# S6E1C3xD register map
Vendor: Cypress; File version: 2.1
CPU: CM0PLUS r0p1, little endian, no MPU, no FPU, 2 interrupt priority bits
Registers are 32-bit, read-write, reset 0x0 unless marked. A register's access mark holds for its fields unless they carry their own. Offsets are from the block's base; [hi:lo] are bit positions; {n}, {i} and the like mark numbered series.

## LVD — Low-voltage Detection
Base 0x40035000
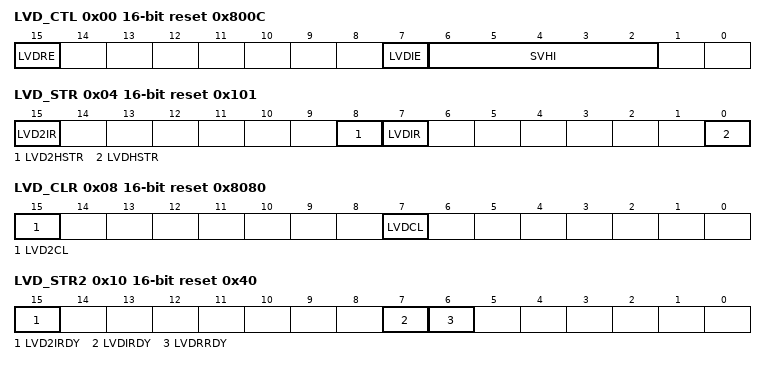
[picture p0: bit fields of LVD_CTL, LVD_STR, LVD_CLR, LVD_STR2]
0x00 LVD_CTL 16-bit reset 0x800C — Low-voltage Detection Voltage Control Register [BHW]
  [15] LVDRE — Low-voltage detection reset operation enable bit
  [7] LVDIE — Low-voltage detection interrupt enable bit
  [6:2] SVHI — Low-voltage detection interrupt voltage setting bits
0x04 LVD_STR 16-bit ro reset 0x101 — Low-voltage Detection Interrupt Factor Register [BHW]
  [15] LVD2IR — Low-voltage detection 2 interrupt factor bit
  [8] LVD2HSTR — Voltage of VCC is higher than the setting of SVH2RLI
  [7] LVDIR — Low-voltage detection interrupt factor bit
  [0] LVDHSTR — Voltage of VCC is higher than the setting of SVHRLI
0x08 LVD_CLR 16-bit reset 0x8080 — Low-voltage Detection Interrupt Factor Clear Register [BHW]
  [15] LVD2CL — Low-voltage detection 2 interrupt factor clear bit
  [7] LVDCL — Low-voltage detection interrupt factor clear bit
0x0C LVD_RLR reset 0x1 — Low-voltage Detection Voltage Protection Register [W]
  [31:0] LVDLCK — Low-voltage Detection Voltage Control Register protection bits
0x10 LVD_STR2 16-bit ro reset 0x40 — Low-voltage Detection Circuit Status Register [BHW]
  [15] LVD2IRDY — Low-voltage detection 2 interrupt status flag
  [7] LVDIRDY — Low-voltage detection interrupt status flag
  [6] LVDRRDY — Low-voltage detection reset status flag

## DS — Low Power Consumption Mode Registers
Base 0x40035100
0x00 REG_CTL 8-bit reset 0x4 — Sub Oscillation Circuit Power Supply Control Register [BHW]
  [2:1] ISUBSEL — Sub oscillation circuit current setting bits
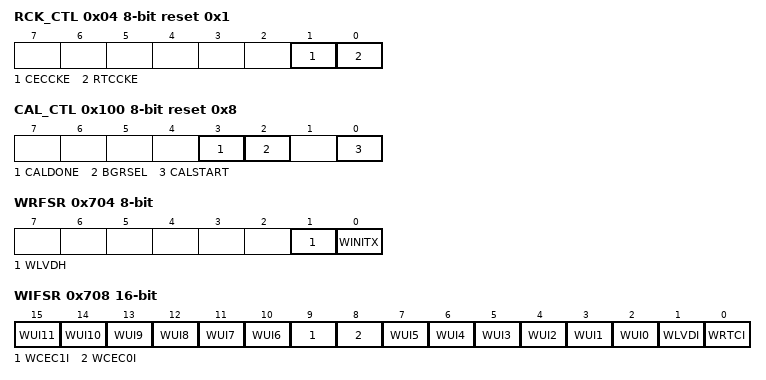
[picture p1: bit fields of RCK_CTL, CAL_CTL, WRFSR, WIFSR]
0x04 RCK_CTL 8-bit reset 0x1 — Sub Clock Control Register [BHW]
  [1] CECCKE — CEC clock control bit
  [0] RTCCKE — RTC clock control bit
0x10 MOSC_CTL 8-bit reset 0x4 — Main Oscillation Crystal Type Selection Control Register [BHW]
  [2:1] IMAINSEL — Main oscillation circuit current setting bits
0x100 CAL_CTL 8-bit reset 0x8 — Vref Calibration Control Register [BHW]
  [3] CALDONE ro — Vref Calibration Done Flag
  [2] BGRSEL — Vref Select Bit
  [0] CALSTART — Vref Calibration Start Bit
0x108 CAL_KEY reset 0x1 — Vref Calibration Security Key Register [W]
0x700 PMD_CTL 8-bit — RTC Mode Control Register [BHW]
  [0] RTCE — RTC mode control bit
0x704 WRFSR 8-bit ro — Deep Standby Return Factor Register 1 [BHW]
  [1] WLVDH — Low-voltage detection reset return bit
  [0] WINITX — INITX pin input reset return bit
0x708 WIFSR 16-bit ro — Deep Standby Return Factor Register 2 [BHW]
  [n+4] WUI{n} (n=6..11) — WKUP{n} pin input return bit
  [9] WCEC1I — CEC ch.1 interrupt return bit
  [8] WCEC0I — CEC ch.0 interrupt return bit
  [n+2] WUI{n} (n=0..5) — WKUP{n} pin input return bit
  [1] WLVDI — LVD interrupt return bit
  [0] WRTCI — RTC interrupt return bit
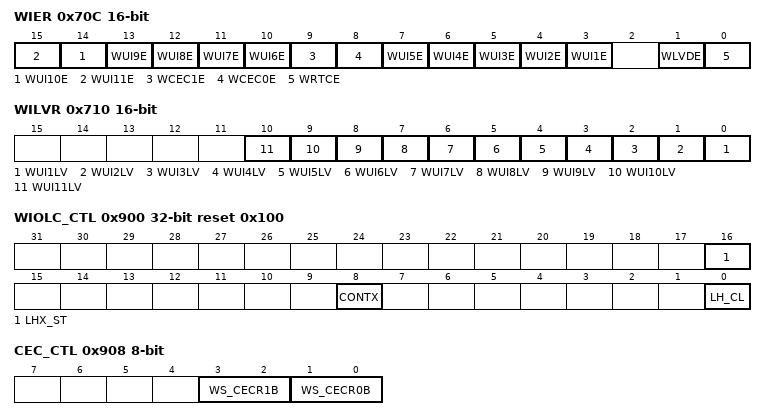
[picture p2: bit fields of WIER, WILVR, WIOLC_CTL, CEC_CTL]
0x70C WIER 16-bit — Deep Standby Return Enable Register [BHW]
  [n+4] WUI{n}E ro (n=6..11) — WKUP{n} pin input return enable bit
  [9] WCEC1E — HDMI-CEC/ Remote Control Reception ch.1 interrupt return enable bit
  [8] WCEC0E — HDMI-CEC/ Remote Control Reception ch.0 interrupt return enable bit
  [n+2] WUI{n}E (n=1..5) — WKUP{n} pin input return enable bit
  [1] WLVDE — LVD interrupt return enable bit
  [0] WRTCE — RTC interrupt return enable bit
0x710 WILVR 16-bit — WKUP Pin Input Level Register [BHW]
  [n-1] WUI{n}LV (n=1..11) — WKUP{n} pin input level select bit
0x714 DSRAMR 8-bit — Deep Standby RAM Retention Register [BHW]
  [1:0] SRAMR — On-chip SRAM retention control bits
{0x7FF+i} BUR{i:02} 8-bit (i=1..16) — Backup Register {i:02} [BHW]
0x900 WIOLC_CTL reset 0x100 — IO State hold control Register [BHW]
  [16] LHX_ST ro — IO state bit
  [8] CONTX — IO State hold function enable bit
  [0] LH_CL — IO State hold release bit
0x904 SUBOSC_CTL 8-bit reset 0x1 — Sub Oscillator IO Control Register [BHW]
  [1:0] SUBXC — Sub Clock (Oscillation) Pin Setting Register [BHW]
0x908 CEC_CTL 8-bit — CEC Input/Output Control Register [BHW]
  [3:2] WS_CECR1B — CEC1 input/output selection bits
  [1:0] WS_CECR0B — CEC0 input/output selection bits
0x90C DEBUG_SW_CTL 8-bit reset 0x1 — Serial Wire Debug Control Register [BHW]
  [0] DBG_EN — SWD enable bits
